VERSION ""

NS_ :

BS_:

BU_:
VAL_TABLE_ THDiff_Error 1 "正常" 0 "异常" ;
VAL_TABLE_ THCAN_Error 1 "正常" 0 "异常" ;

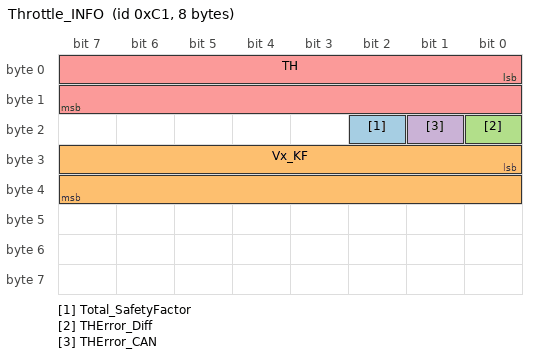
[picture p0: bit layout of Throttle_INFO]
BO_ 193 Throttle_INFO: 8 Vector__XXX
 SG_ Total_SafetyFactor : 18|1@1+ (1,0) [0|1] "" Vector__XXX
 SG_ Vx_KF : 24|16@1- (0.01,0) [-327.68|327.67] "kph" Vector__XXX
 SG_ THError_Diff : 16|1@1+ (1,0) [0|1] "" Vector__XXX
 SG_ THError_CAN : 17|1@1+ (1,0) [0|1] "" Vector__XXX
 SG_ TH : 0|16@1+ (0.01,0) [0|655.35] "" Vector__XXX

BA_DEF_  "BusType" STRING ;
BA_DEF_DEF_  "BusType" "CAN";
VAL_ 193 THError_Diff 1 "正常" 0 "异常" ;
VAL_ 193 THError_CAN 1 "正常" 0 "异常" ;
